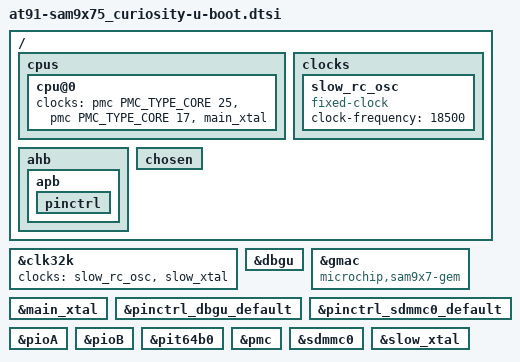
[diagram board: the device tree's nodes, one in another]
// SPDX-License-Identifier: (GPL-2.0+ OR MIT)
/*
 * at91-sam9x75_curiosity-u-boot.dtsi - Device Tree file for SAM9X75
 * CURIOSITY board.
 *
 * Copyright (C) 2025 Microchip Technology Inc. and its subsidiaries
 *
 * Author: Manikandan Muralidharan <manikandan.m@microchip.com>
 */

/ {
	cpus {
		cpu@0 {
			clocks = <&pmc PMC_TYPE_CORE 25>, <&pmc PMC_TYPE_CORE 17>, <&main_xtal>;
			clock-names = "cpu", "master", "xtal";
		};
	};

	clocks {
		slow_rc_osc: slow_rc_osc {
			compatible = "fixed-clock";
			#clock-cells = <0>;
			clock-frequency = <18500>;
		};
	};

	ahb {
		bootph-all;

		apb {
			bootph-all;

			pinctrl {
				bootph-all;
			};
		};
	};

	chosen {
		bootph-all;
	};
};

&clk32k {
	bootph-all;
	clocks = <&slow_rc_osc>, <&slow_xtal>;
};

&dbgu {
	bootph-all;
};

&gmac {
	compatible = "microchip,sam9x7-gem", "cdns,sama7g5-gem";
};

&main_xtal {
	bootph-all;
};

&pinctrl_dbgu_default {
	bootph-all;
};

&pinctrl_sdmmc0_default {
	bootph-all;
};

&pioA {
	bootph-all;
};

&pioB {
	bootph-all;
};

&pit64b0 {
	bootph-all;
};

&pmc {
	bootph-all;
};

&sdmmc0 {
	bootph-all;
};

&slow_xtal {
	bootph-all;
};

&slow_rc_osc {
	bootph-all;
};
